AUTOSAR XML (schema 00044)
package /IvdSfdAResourceConsumption/SwAddrMethods
  sw addr method CODE: memory-allocation-keyword-policy=ADDR-METHOD-SHORT-NAME, section-type=CODE
package /ComponentTypes
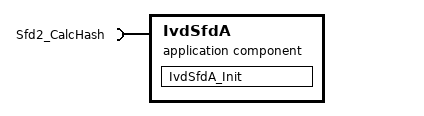
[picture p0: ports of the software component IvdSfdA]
  application sw component type IvdSfdA
    require port Sfd2_CalcHash: required-com-specs=[CalcHash_Data, CalcHash_Hash, CalcHash_Setup], required-interface=Sfd2_CalcHash
    behavior IvdSfdA_InternalBehavior
      init event SfdA_InitEvent: start-on-event=IvdSfdA_Init
      runnable IvdSfdA_Init
        sync call SC_Sfd2_CalcHash_Data: operation=Sfd2_CalcHash.CalcHash_Data, timeout=0
        sync call SC_Sfd2_CalcHash_Hash: operation=Sfd2_CalcHash.CalcHash_Hash, timeout=0
        sync call SC_Sfd2_CalcHash_Setup: operation=Sfd2_CalcHash.CalcHash_Setup, timeout=0
  swc implementation IvdSfdA_Implementation: vendor-id=75, behavior=IvdSfdA_InternalBehavior
    code-descriptors:
      code Default: artifact-descriptors=autosar-engineering-object={short-label=Default, category=SWSRC}
    resource consumption ResourceConsumption
      memory section CODE: sw-addrmethod=CODE
package /DataTypes
  impl type Sfd2_32ByteHash_Type: category=ARRAY, sw-calibration-access=READ-ONLY, type-emitter=RTE
    element Element: array-size=32, array-size-semantics=FIXED-SIZE, implementation-data-type=uint8
  impl type Sfd2_DidArray_Type: category=ARRAY, sw-calibration-access=READ-ONLY, type-emitter=RTE
    element Element: array-size=64, array-size-semantics=FIXED-SIZE, implementation-data-type=uint16
package /PortInterfaces
  client server interface Sfd2_CalcHash
    operation CalcHash_Data: possible-error=[IVD_E_DID_INVALID, IVD_E_NOT_OK]
      arg numDIDs: type=uint16, direction=IN, server-argument-impl-policy=USE-ARGUMENT-TYPE
      arg DIDs: type=Sfd2_DidArray_Type, direction=IN, server-argument-impl-policy=USE-ARGUMENT-TYPE
    operation CalcHash_Hash: possible-error=[IVD_E_NOT_OK, IVD_E_PENDING]
      arg ptrHashValue: type=Sfd2_32ByteHash_Type, direction=OUT, server-argument-impl-policy=USE-ARGUMENT-TYPE
    operation CalcHash_Setup: possible-error=[IVD_E_NOT_OK, IVD_E_PENDING, IVD_E_SMALL_BUFFER]
      arg lengthDIDs: type=uint16, direction=IN, server-argument-impl-policy=USE-ARGUMENT-TYPE
    4 x error:
      IVD_E_DID_INVALID: error-code=3
      IVD_E_NOT_OK: error-code=1
      IVD_E_PENDING: error-code=10
      IVD_E_SMALL_BUFFER: error-code=2
